# M55M1 register map
File version: 1.0
Registers are 32-bit, read-write, reset 0x0 unless marked. A register's access mark holds for its fields unless they carry their own. Offsets are from the block's base; [hi:lo] are bit positions; {n}, {i} and the like mark numbered series; 'fields as' and 'values as' point back to an identical list.

## GPIO — GPIO Register Map
Base 0x40229000
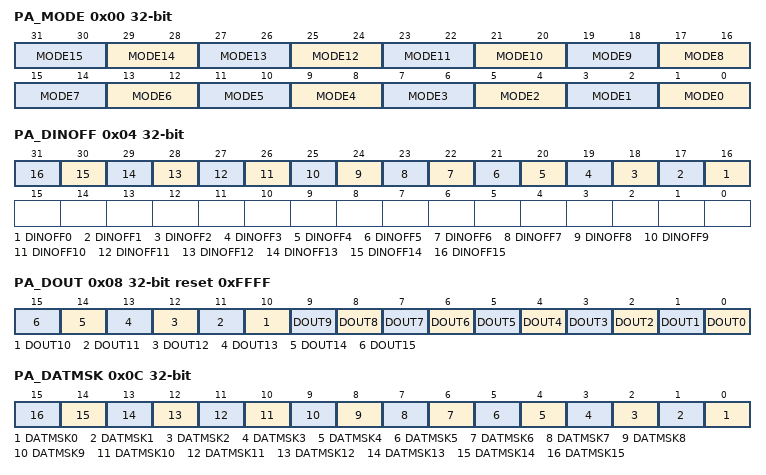
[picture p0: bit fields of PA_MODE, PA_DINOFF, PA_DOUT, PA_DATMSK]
0x00 PA_MODE — PA I/O Mode Control
  [all] fields
    0=Px.n is in Input mode; 1=Px.n is in Push-pull Output mode; 2=Px.n is in Open-drain Output mode; 3=Px.n is in Quasi-bidirectional mode
  [2n+1:2n] MODE{n} (n=0..15) — Port A-J I/O Pin[n] Mode Control. Determine each I/O mode of Px.n pins. Note 2: Each INT pins is Input mode
0x04 PA_DINOFF — PA Digital Input Path Disable Control
  [all] fields
    0=Px.n digital input path Enabled; 1=Px.n digital input path Disabled (digital input tied to low)
  [n+16] DINOFF{n} (n=0..15) — Port A-J Pin[n] Digital Input Path Disable Bit. Each of these bits is used to control if the digital input path of corresponding Px.n pin is disabled. If input is analog signal, users can disable Px.n digital input path to avoid input current leakage.
0x08 PA_DOUT reset 0xFFFF — PA Data Output Value
  [all] fields
    0=Px.n will drive Low if the Px.n pin is configured as Push-pull output, Open-drain output or Quasi-bidirectional mode; 1=Px.n will drive High if the Px.n pin is configured as Push-pull output or Quasi-bidirectional mode
  [n] DOUT{n} (n=0..15) — Port A-J Pin[n] Output Value. Each of these bits controls the status of a Px.n pin when the Px.n is configured as Push-pull output, Open-drain output or Quasi-bidirectional mode.
0x0C PA_DATMSK — PA Data Output Write Mask
  [all] fields
    0=Corresponding DOUT (Px_DOUT[n]) bit can be updated; 1=Corresponding DOUT (Px_DOUT[n]) bit protected
  [n] DATMSK{n} (n=0..15) — Port A-J Pin[n] Data Output Write Mask. These bits are used to protect the corresponding DOUT (Px_DOUT[n]) bit. When the DATMSK (Px_DATMSK[n]) bit is set to 1, the corresponding DOUT (Px_DOUT[n]) bit is protected. If the write signal is masked, writing data to the protect bit is ignored.
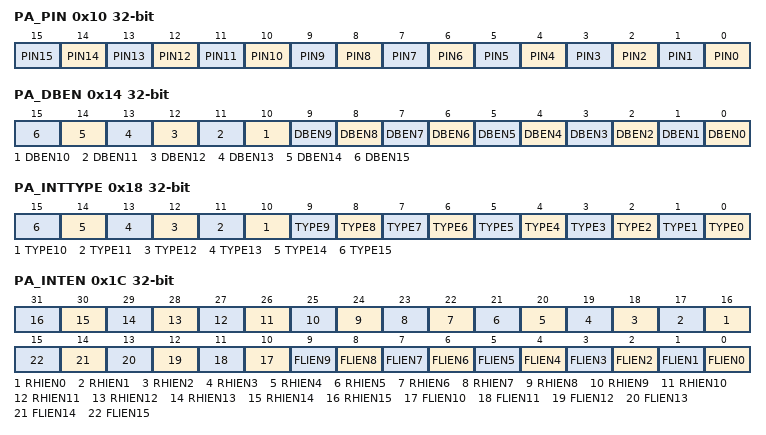
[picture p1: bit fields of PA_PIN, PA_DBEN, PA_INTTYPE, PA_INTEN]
0x10 PA_PIN ro (reset mask 0xFFFF0000) — PA Pin Value
  [n] PIN{n} (n=0..15) — Port A-J Pin[n] Pin Value. Each bit of the register reflects the actual status of the respective Px.n pin. If the bit is 1, it indicates the corresponding pin status is high; else the pin status is low. Note:
0x14 PA_DBEN — PA De-bounce Enable Control Register
  [all] fields
    0=Px.n de-bounce function Disabled; 1=Px.n de-bounce function Enabled
  [n] DBEN{n} (n=0..15) — Port A-J Pin[n] Input Signal De-bounce Enable Bit. The DBEN[n] bit is used to enable the de-bounce function for each corresponding bit. If the input signal pulse width cannot be sampled by continuous two de-bounce sample cycle, the input signal transition is seen as the signal bounce and will not trigger the interrupt. The de-bounce clock source is controlled by DBCLKSRC (GPIO_DBCTL [4]), one de-bounce sample cycle period is controlled by DBCLKSEL (GPIO_DBCTL [3:0]). Note 2: Set Px_DBEN after configuring Px_DBCTL.
0x18 PA_INTTYPE — PA Interrupt Trigger Type Control
  [all] fields
    0=Edge trigger interrupt; 1=Level trigger interrupt
  [n] TYPE{n} (n=0..15) — Port A-J Pin[n] Edge or Level Detection Interrupt Trigger Type Control. TYPE (Px_INTTYPE[n]) bit is used to control the triggered interrupt is by level trigger or by edge trigger. If the interrupt is by edge trigger, the trigger source can be controlled by de-bounce. If the interrupt is by level trigger, the input source is sampled by one HCLK0 clock and generates the interrupt.
0x1C PA_INTEN — PA Interrupt Enable Control Register
  [n+16] RHIEN{n} (n=0..15) — Port A-J Pin[n] Rising Edge or High Level Interrupt Trigger Type Enable Bit. The RHIEN (Px_INTEN[n+16]) bit is used to enable the interrupt for each of the corresponding input Px.n pin. Set bit to 1 also enable the pin wake-up function. When setting the RHIEN (Px_INTEN[n+16]) bit to 1 : If the interrupt is level trigger (TYPE (Px_INTTYPE[n]) bit is set to 1), the input Px.n pin will generate the interrupt while this pin state is at high level. If the interrupt is edge trigger (TYPE (Px_INTTYPE[n]) bit is set to 0), the input Px.n pin will generate the interrupt while this pin state changed from low to high. Note 2: Clear Px_INTTYPE after configuring GPIO and then enable Px_INTEN.
    0=Px.n level high or low to high interrupt Disabled; 1=Px.n level high or low to high interrupt Enabled
  [n] FLIEN{n} (n=0..15) — Port A-J Pin[n] Falling Edge or Low Level Interrupt Trigger Type Enable Bit. The FLIEN (Px_INTEN[n]) bit is used to enable the interrupt for each of the corresponding input Px.n pin. Set bit to 1 also enable the pin wake-up function. When setting the FLIEN (Px_INTEN[n]) bit to 1 : If the interrupt is level trigger (TYPE (Px_INTTYPE[n]) bit is set to 1), the input Px.n pin will generate the interrupt while this pin state is at low level. If the interrupt is edge trigger(TYPE (Px_INTTYPE[n]) bit is set to 0), the input Px.n pin will generate the interrupt while this pin state changed from high to low. Note 2: Write 1 clear Px_INTTYPE after configuring GPIO and then enable Px_INTEN.
    0=Px.n level low or high to low interrupt Disabled; 1=Px.n level low or high to low interrupt Enabled
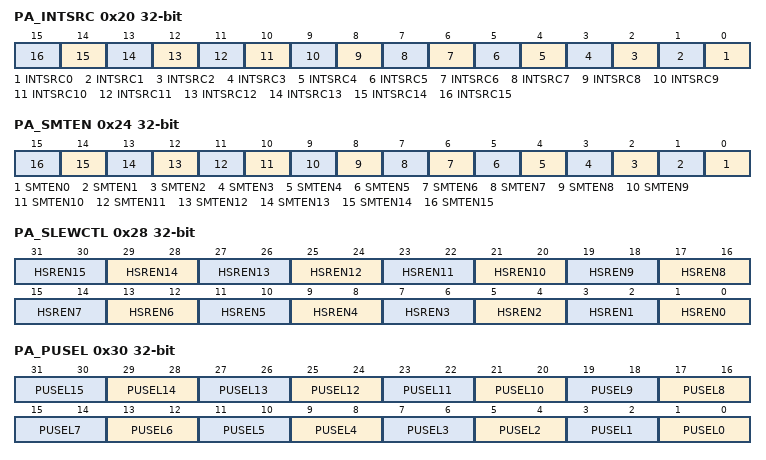
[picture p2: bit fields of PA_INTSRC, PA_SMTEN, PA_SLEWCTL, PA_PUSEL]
0x20 PA_INTSRC (reset mask 0xFFFF0000) — PA Interrupt Source Flag
  [all] fields
    0=No interrupt at Px.n; 1=Px.n generates an interrupt
  [n] INTSRC{n} write-1-clears (n=0..15) — Port A-J Pin[n] Interrupt Source Flag (Write 1 to Clear)
0x24 PA_SMTEN — PA Input Schmitt Trigger Enable Register
  [all] fields
    0=Px.n input schmitt trigger function Disabled; 1=Px.n input schmitt trigger function Enabled
  [n] SMTEN{n} (n=0..15) — Port A-J Pin[n] Input Schmitt Trigger Enable Bit
0x28 PA_SLEWCTL — PA High Slew Rate Control Register
  [all] fields
    0=Px.n output with normal slew rate mode (maximum 20 MHz at 2.7V); 1=Px.n output with high slew rate mode (maximum 40 MHz at 2.7V); 2=Px.n output with fast slew rate mode (maximum 80 MHz at 2.7V); 3=Px.n output with fast slew rate mode (maximum 100 MHz cloud at 35pF / maximum 120 MHz cloud at 25pF at 2.7V)
  [2n+1:2n] HSREN{n} (n=0..15) — Port A-J Pin[n] High Slew Rate Control
0x30 PA_PUSEL — PA Pull-up and Pull-down Selection Register
  [all] fields
    0=Px.n pull-up and pull-down disable; 1=Px.n pull-up enable; 2=Px.n pull-down enable
  [2n+1:2n] PUSEL{n} (n=0..15) — Port A-J Pin[n] Pull-up and Pull-down Enable Register. Determine each I/O Pull-up/pull-down of Px.n pins.
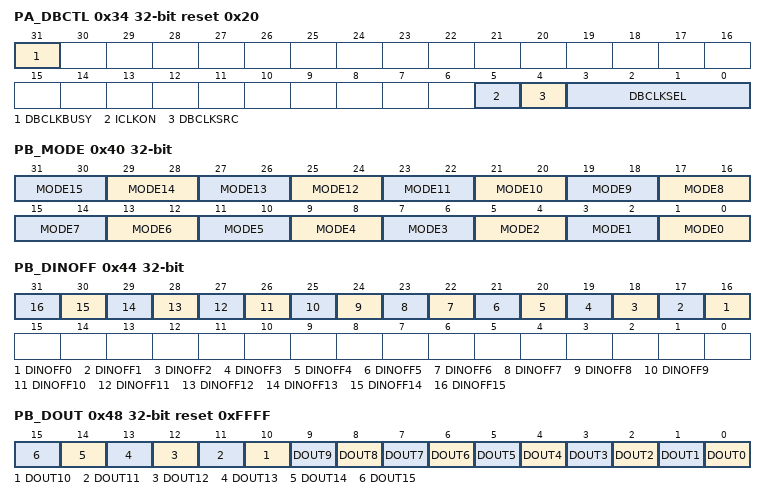
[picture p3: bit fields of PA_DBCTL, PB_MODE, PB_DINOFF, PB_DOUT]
0x34 PA_DBCTL reset 0x20 — PA Interrupt De-bounce Control Register
  [31] DBCLKBUSY ro — De-bounce Clock Switching Busy Flag - Secure Only (Read Only). This bit is set when de-bounce clock source is changed by setting DBCLKSRC(Px_DBCTL[4]). And it is cleared after de-bounce clock source switching is finished. De-bounce function can work normally after de-bounce clock switch done.
    0=De-bounce clock switch done; 1=De-bounce clock is switching
  [5] ICLKON — Interrupt Clock on Mode - Secure Only
    0=Edge detection circuit is active only if I/O pin corresponding RHIEN (Px_INTEN[n+16])/FLIEN (Px_INTEN[n]) bit is set to 1. If corresponding RHIEN or FLIEN is 0, the clock of I/O detect circuit is stopped and interrupt source flag(Px_INTSRC) cannot be clear also; 1=All I/O pins edge detection circuit is always active after reset
  [4] DBCLKSRC — De-bounce Counter Clock Source Selection - Secure Only
    0=De-bounce counter clock source is the HCLK0; 1=De-bounce counter clock source is the 32 kHz internal low speed RC oscillator (LIRC)
  [3:0] DBCLKSEL — De-bounce Sampling Cycle Selection - Secure Only
    0=Sample interrupt input once per 1 clocks; 1=Sample interrupt input once per 2 clocks; 2=Sample interrupt input once per 4 clocks; 3=Sample interrupt input once per 8 clocks; 4=Sample interrupt input once per 16 clocks; 5=Sample interrupt input once per 32 clocks; 6=Sample interrupt input once per 64 clocks; 7=Sample interrupt input once per 128 clocks; 8=Sample interrupt input once per 256 clocks; 9=Sample interrupt input once per 2*256 clocks; 10=Sample interrupt input once per 4*256 clocks; 11=Sample interrupt input once per 8*256 clocks; 12=Sample interrupt input once per 16*256 clocks; 13=Sample interrupt input once per 32*256 clocks; 14=Sample interrupt input once per 64*256 clocks; 15=Sample interrupt input once per 128*256 clocks
0x40 PB_MODE — PB I/O Mode Control
  fields as PA_MODE
0x44 PB_DINOFF — PB Digital Input Path Disable Control
  fields as PA_DINOFF
0x48 PB_DOUT reset 0xFFFF — PB Data Output Value
  fields as PA_DOUT
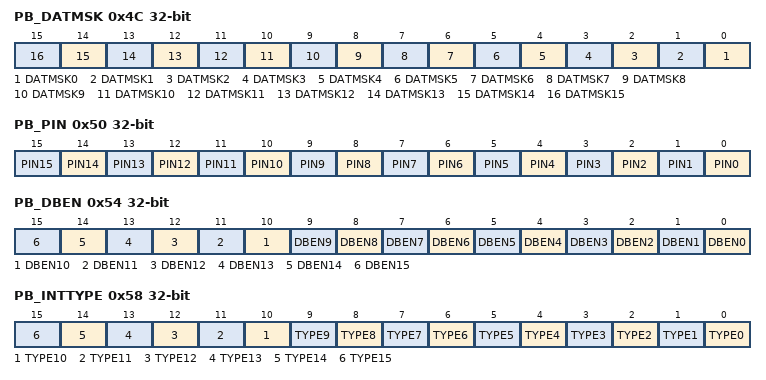
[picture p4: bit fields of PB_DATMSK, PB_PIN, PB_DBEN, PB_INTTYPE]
0x4C PB_DATMSK — PB Data Output Write Mask
  fields as PA_DATMSK
0x50 PB_PIN ro (reset mask 0xFFFF0000) — PB Pin Value
  fields as PA_PIN
0x54 PB_DBEN — PB De-bounce Enable Control Register
  fields as PA_DBEN
0x58 PB_INTTYPE — PB Interrupt Trigger Type Control
  fields as PA_INTTYPE
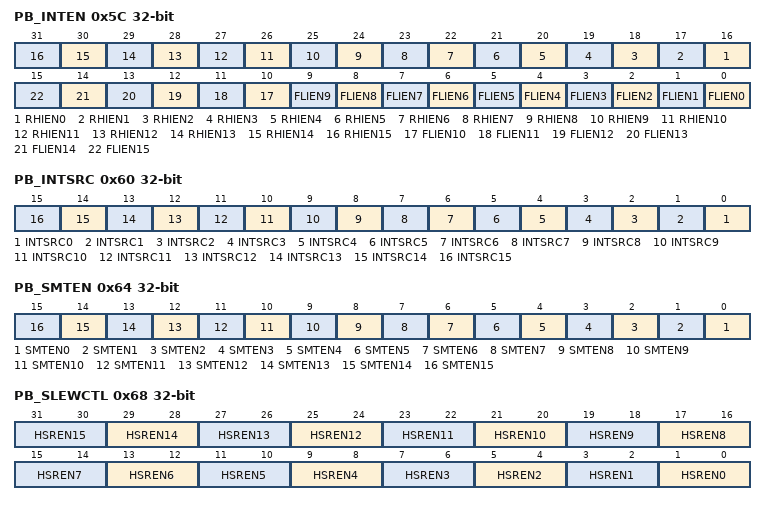
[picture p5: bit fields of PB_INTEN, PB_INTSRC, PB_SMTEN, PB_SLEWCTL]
0x5C PB_INTEN — PB Interrupt Enable Control Register
  fields as PA_INTEN
0x60 PB_INTSRC (reset mask 0xFFFF0000) — PB Interrupt Source Flag
  fields as PA_INTSRC
0x64 PB_SMTEN — PB Input Schmitt Trigger Enable Register
  fields as PA_SMTEN
0x68 PB_SLEWCTL — PB High Slew Rate Control Register
  fields as PA_SLEWCTL
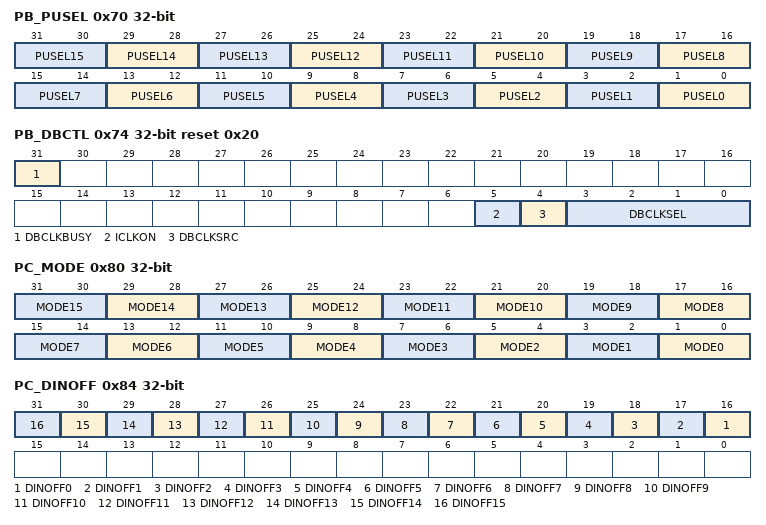
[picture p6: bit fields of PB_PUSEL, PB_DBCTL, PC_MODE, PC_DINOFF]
0x70 PB_PUSEL — PB Pull-up and Pull-down Selection Register
  fields as PA_PUSEL
0x74 PB_DBCTL reset 0x20 — PB Interrupt De-bounce Control Register
  fields as PA_DBCTL
0x80 PC_MODE — PC I/O Mode Control
  fields as PA_MODE
0x84 PC_DINOFF — PC Digital Input Path Disable Control
  fields as PA_DINOFF
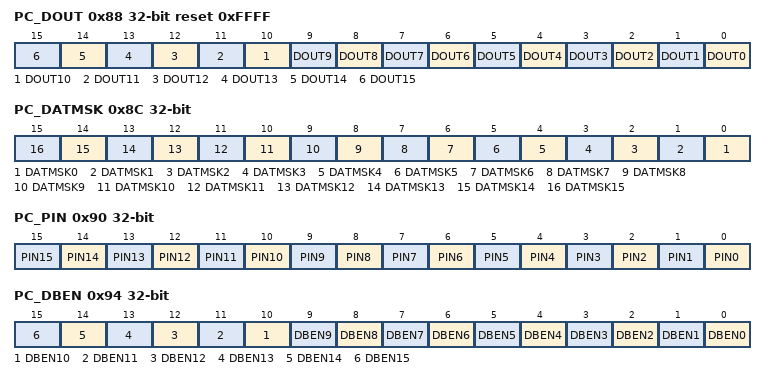
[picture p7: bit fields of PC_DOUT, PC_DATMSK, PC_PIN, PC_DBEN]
0x88 PC_DOUT reset 0xFFFF — PC Data Output Value
  fields as PA_DOUT
0x8C PC_DATMSK — PC Data Output Write Mask
  fields as PA_DATMSK
0x90 PC_PIN ro (reset mask 0xFFFF0000) — PC Pin Value
  fields as PA_PIN
0x94 PC_DBEN — PC De-bounce Enable Control Register
  fields as PA_DBEN
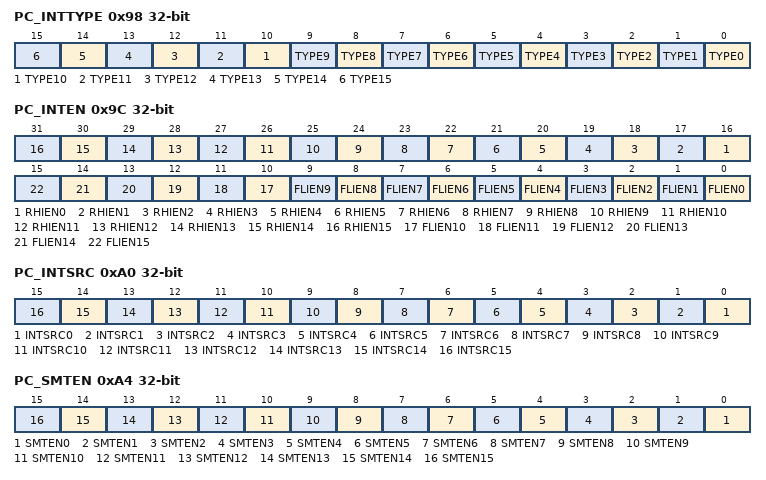
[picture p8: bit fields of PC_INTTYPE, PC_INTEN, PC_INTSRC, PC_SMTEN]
0x98 PC_INTTYPE — PC Interrupt Trigger Type Control
  fields as PA_INTTYPE
0x9C PC_INTEN — PC Interrupt Enable Control Register
  fields as PA_INTEN
0xA0 PC_INTSRC (reset mask 0xFFFF0000) — PC Interrupt Source Flag
  fields as PA_INTSRC
0xA4 PC_SMTEN — PC Input Schmitt Trigger Enable Register
  fields as PA_SMTEN
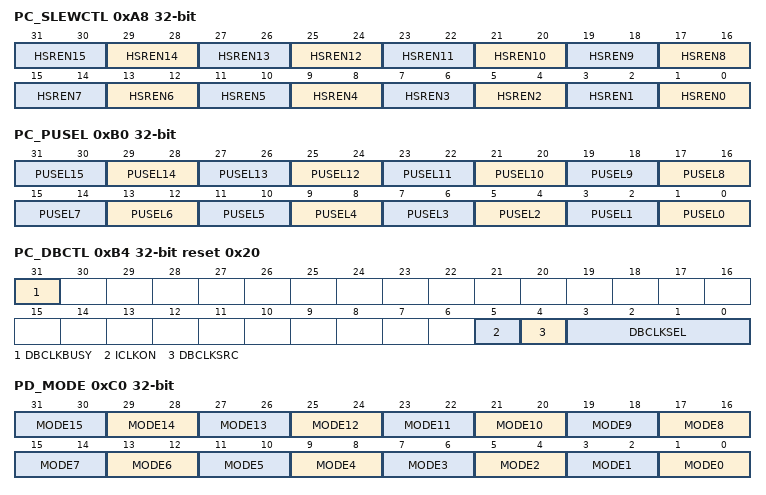
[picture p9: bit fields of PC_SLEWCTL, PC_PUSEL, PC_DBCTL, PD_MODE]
0xA8 PC_SLEWCTL — PC High Slew Rate Control Register
  fields as PA_SLEWCTL
0xB0 PC_PUSEL — PC Pull-up and Pull-down Selection Register
  fields as PA_PUSEL
0xB4 PC_DBCTL reset 0x20 — PC Interrupt De-bounce Control Register
  fields as PA_DBCTL
0xC0 PD_MODE — PD I/O Mode Control
  fields as PA_MODE
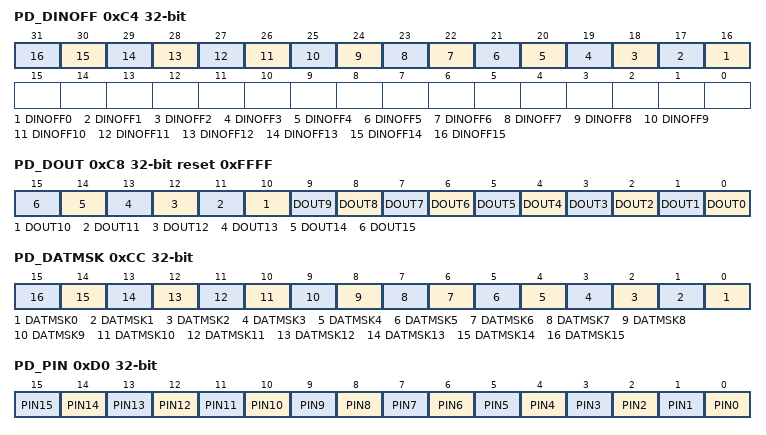
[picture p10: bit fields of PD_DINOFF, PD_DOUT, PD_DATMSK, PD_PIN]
0xC4 PD_DINOFF — PD Digital Input Path Disable Control
  fields as PA_DINOFF
0xC8 PD_DOUT reset 0xFFFF — PD Data Output Value
  fields as PA_DOUT
0xCC PD_DATMSK — PD Data Output Write Mask
  fields as PA_DATMSK
0xD0 PD_PIN ro (reset mask 0xFFFF0000) — PD Pin Value
  fields as PA_PIN
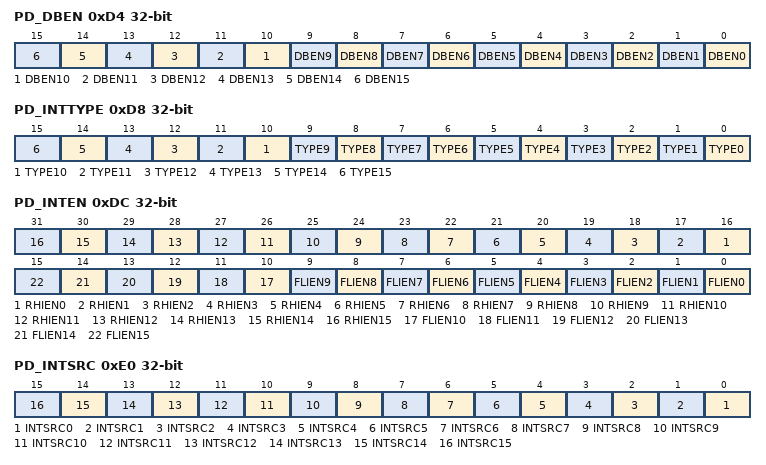
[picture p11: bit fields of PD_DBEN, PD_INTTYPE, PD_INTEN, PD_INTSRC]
0xD4 PD_DBEN — PD De-bounce Enable Control Register
  fields as PA_DBEN
0xD8 PD_INTTYPE — PD Interrupt Trigger Type Control
  fields as PA_INTTYPE
0xDC PD_INTEN — PD Interrupt Enable Control Register
  fields as PA_INTEN
0xE0 PD_INTSRC (reset mask 0xFFFF0000) — PD Interrupt Source Flag
  fields as PA_INTSRC
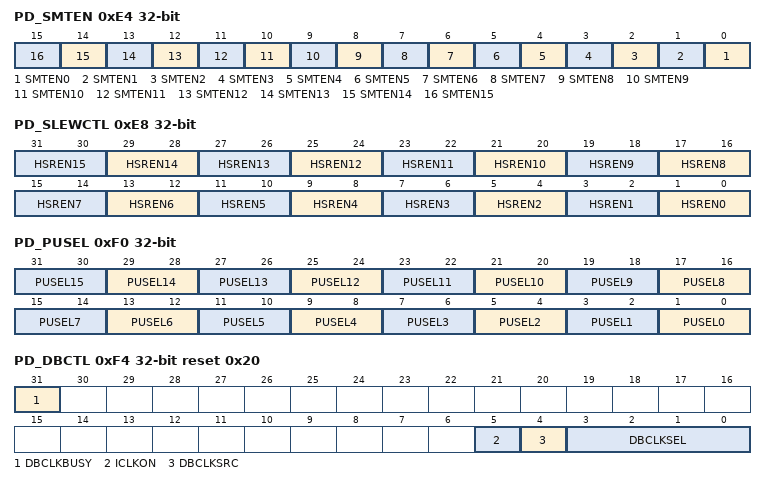
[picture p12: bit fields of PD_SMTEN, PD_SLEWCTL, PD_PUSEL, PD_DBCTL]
0xE4 PD_SMTEN — PD Input Schmitt Trigger Enable Register
  fields as PA_SMTEN
0xE8 PD_SLEWCTL — PD High Slew Rate Control Register
  fields as PA_SLEWCTL
0xF0 PD_PUSEL — PD Pull-up and Pull-down Selection Register
  fields as PA_PUSEL
0xF4 PD_DBCTL reset 0x20 — PD Interrupt De-bounce Control Register
  fields as PA_DBCTL
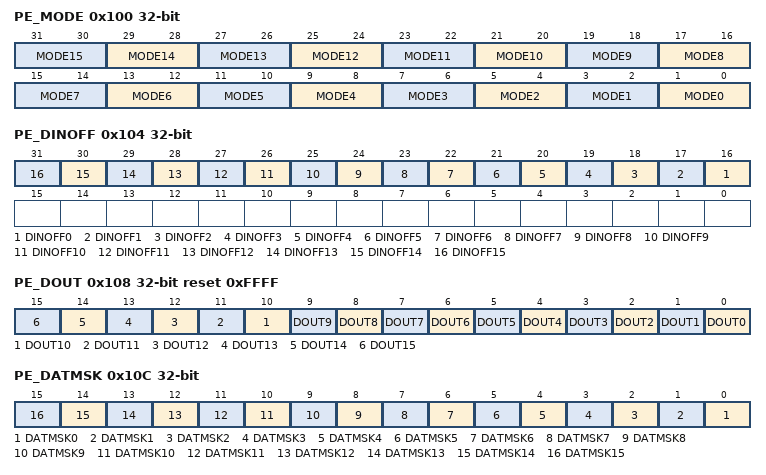
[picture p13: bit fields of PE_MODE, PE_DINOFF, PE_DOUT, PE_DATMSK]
0x100 PE_MODE — PE I/O Mode Control
  fields as PA_MODE
0x104 PE_DINOFF — PE Digital Input Path Disable Control
  fields as PA_DINOFF
0x108 PE_DOUT reset 0xFFFF — PE Data Output Value
  fields as PA_DOUT
0x10C PE_DATMSK — PE Data Output Write Mask
  fields as PA_DATMSK
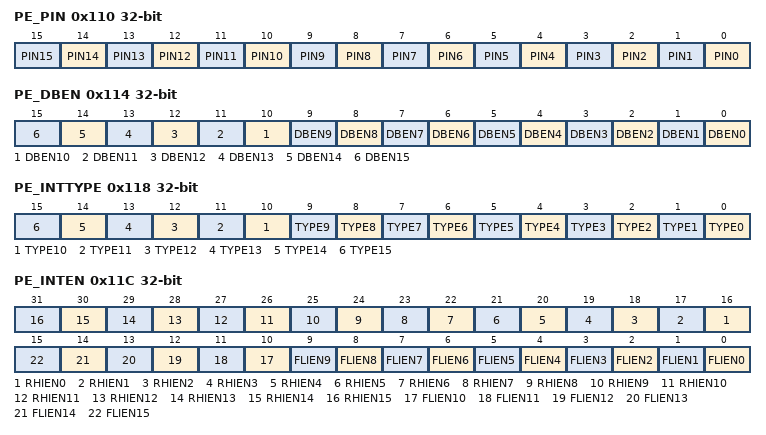
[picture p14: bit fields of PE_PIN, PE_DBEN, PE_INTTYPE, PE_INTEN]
0x110 PE_PIN ro (reset mask 0xFFFF0000) — PE Pin Value
  fields as PA_PIN
0x114 PE_DBEN — PE De-bounce Enable Control Register
  fields as PA_DBEN
0x118 PE_INTTYPE — PE Interrupt Trigger Type Control
  fields as PA_INTTYPE
0x11C PE_INTEN — PE Interrupt Enable Control Register
  fields as PA_INTEN
0x120 PE_INTSRC (reset mask 0xFFFF0000) — PE Interrupt Source Flag
  fields as PA_INTSRC
0x124 PE_SMTEN — PE Input Schmitt Trigger Enable Register
  fields as PA_SMTEN
0x128 PE_SLEWCTL — PE High Slew Rate Control Register
  fields as PA_SLEWCTL
0x130 PE_PUSEL — PE Pull-up and Pull-down Selection Register
  fields as PA_PUSEL
0x134 PE_DBCTL reset 0x20 — PE Interrupt De-bounce Control Register
  fields as PA_DBCTL
0x140 PF_MODE — PF I/O Mode Control
  fields as PA_MODE
0x144 PF_DINOFF — PF Digital Input Path Disable Control
  fields as PA_DINOFF
0x148 PF_DOUT reset 0xFFFF — PF Data Output Value
  fields as PA_DOUT
0x14C PF_DATMSK — PF Data Output Write Mask
  fields as PA_DATMSK
0x150 PF_PIN ro (reset mask 0xFFFF0000) — PF Pin Value
  fields as PA_PIN
0x154 PF_DBEN — PF De-bounce Enable Control Register
  fields as PA_DBEN
0x158 PF_INTTYPE — PF Interrupt Trigger Type Control
  fields as PA_INTTYPE
0x15C PF_INTEN — PF Interrupt Enable Control Register
  fields as PA_INTEN
0x160 PF_INTSRC (reset mask 0xFFFF0000) — PF Interrupt Source Flag
  fields as PA_INTSRC
0x164 PF_SMTEN — PF Input Schmitt Trigger Enable Register
  fields as PA_SMTEN
0x168 PF_SLEWCTL — PF High Slew Rate Control Register
  fields as PA_SLEWCTL
0x170 PF_PUSEL — PF Pull-up and Pull-down Selection Register
  fields as PA_PUSEL
0x174 PF_DBCTL reset 0x20 — PF Interrupt De-bounce Control Register
  fields as PA_DBCTL
0x180 PG_MODE — PG I/O Mode Control
  fields as PA_MODE
0x184 PG_DINOFF — PG Digital Input Path Disable Control
  fields as PA_DINOFF
0x188 PG_DOUT reset 0xFFFF — PG Data Output Value
  fields as PA_DOUT
0x18C PG_DATMSK — PG Data Output Write Mask
  fields as PA_DATMSK
0x190 PG_PIN ro (reset mask 0xFFFF0000) — PG Pin Value
  fields as PA_PIN
0x194 PG_DBEN — PG De-bounce Enable Control Register
  fields as PA_DBEN
0x198 PG_INTTYPE — PG Interrupt Trigger Type Control
  fields as PA_INTTYPE
0x19C PG_INTEN — PG Interrupt Enable Control Register
  fields as PA_INTEN
0x1A0 PG_INTSRC (reset mask 0xFFFF0000) — PG Interrupt Source Flag
  fields as PA_INTSRC
0x1A4 PG_SMTEN — PG Input Schmitt Trigger Enable Register
  fields as PA_SMTEN
0x1A8 PG_SLEWCTL — PG High Slew Rate Control Register
  fields as PA_SLEWCTL
0x1B0 PG_PUSEL — PG Pull-up and Pull-down Selection Register
  fields as PA_PUSEL
0x1B4 PG_DBCTL reset 0x20 — PG Interrupt De-bounce Control Register
  fields as PA_DBCTL
0x1C0 PH_MODE — PH I/O Mode Control
  fields as PA_MODE
0x1C4 PH_DINOFF — PH Digital Input Path Disable Control
  fields as PA_DINOFF
0x1C8 PH_DOUT reset 0xFFFF — PH Data Output Value
  fields as PA_DOUT
0x1CC PH_DATMSK — PH Data Output Write Mask
  fields as PA_DATMSK
0x1D0 PH_PIN ro (reset mask 0xFFFF0000) — PH Pin Value
  fields as PA_PIN
0x1D4 PH_DBEN — PH De-bounce Enable Control Register
  fields as PA_DBEN
0x1D8 PH_INTTYPE — PH Interrupt Trigger Type Control
  fields as PA_INTTYPE
0x1DC PH_INTEN — PH Interrupt Enable Control Register
  fields as PA_INTEN
0x1E0 PH_INTSRC (reset mask 0xFFFF0000) — PH Interrupt Source Flag
  fields as PA_INTSRC
0x1E4 PH_SMTEN — PH Input Schmitt Trigger Enable Register
  fields as PA_SMTEN
0x1E8 PH_SLEWCTL — PH High Slew Rate Control Register
  fields as PA_SLEWCTL
0x1F0 PH_PUSEL — PH Pull-up and Pull-down Selection Register
  fields as PA_PUSEL
0x1F4 PH_DBCTL reset 0x20 — PH Interrupt De-bounce Control Register
  fields as PA_DBCTL
0x200 PI_MODE — PI I/O Mode Control
  fields as PA_MODE
0x204 PI_DINOFF — PI Digital Input Path Disable Control
  fields as PA_DINOFF
0x208 PI_DOUT reset 0xFFFF — PI Data Output Value
  fields as PA_DOUT
0x20C PI_DATMSK — PI Data Output Write Mask
  fields as PA_DATMSK
0x210 PI_PIN ro (reset mask 0xFFFF0000) — PI Pin Value
  fields as PA_PIN
0x214 PI_DBEN — PI De-bounce Enable Control Register
  fields as PA_DBEN
0x218 PI_INTTYPE — PI Interrupt Trigger Type Control
  fields as PA_INTTYPE
0x21C PI_INTEN — PI Interrupt Enable Control Register
  fields as PA_INTEN
0x220 PI_INTSRC (reset mask 0xFFFF0000) — PI Interrupt Source Flag
  fields as PA_INTSRC
0x224 PI_SMTEN — PI Input Schmitt Trigger Enable Register
  fields as PA_SMTEN
0x228 PI_SLEWCTL — PI High Slew Rate Control Register
  fields as PA_SLEWCTL
0x230 PI_PUSEL — PI Pull-up and Pull-down Selection Register
  fields as PA_PUSEL
0x234 PI_DBCTL reset 0x20 — PI Interrupt De-bounce Control Register
  fields as PA_DBCTL
0x240 PJ_MODE — PJ I/O Mode Control
  fields as PA_MODE
0x244 PJ_DINOFF — PJ Digital Input Path Disable Control
  fields as PA_DINOFF
0x248 PJ_DOUT reset 0xFFFF — PJ Data Output Value
  fields as PA_DOUT
0x24C PJ_DATMSK — PJ Data Output Write Mask
  fields as PA_DATMSK
0x250 PJ_PIN ro (reset mask 0xFFFF0000) — PJ Pin Value
  fields as PA_PIN
0x254 PJ_DBEN — PJ De-bounce Enable Control Register
  fields as PA_DBEN
0x258 PJ_INTTYPE — PJ Interrupt Trigger Type Control
  fields as PA_INTTYPE
0x25C PJ_INTEN — PJ Interrupt Enable Control Register
  fields as PA_INTEN
0x260 PJ_INTSRC (reset mask 0xFFFF0000) — PJ Interrupt Source Flag
  fields as PA_INTSRC
0x264 PJ_SMTEN — PJ Input Schmitt Trigger Enable Register
  fields as PA_SMTEN
0x268 PJ_SLEWCTL — PJ High Slew Rate Control Register
  fields as PA_SLEWCTL
0x270 PJ_PUSEL — PJ Pull-up and Pull-down Selection Register
  fields as PA_PUSEL
0x274 PJ_DBCTL reset 0x20 — PJ Interrupt De-bounce Control Register
  fields as PA_DBCTL
{0x440+0x20*i} INT{i}_INNF (i=0..7) — INT{i} Input Noise Filter Register
  [10:8] NFCNT — Noise Filter Count. The register bits control the filter counter to count from 0 to NFCNT.
  [6:4] NFSEL — Noise Filter Clock Selection
    0=Filter clock is HCLK0; 1=Filter clock is HCLK0/2; 2=Filter clock is HCLK0/4; 3=Filter clock is HCLK0/8; 4=Filter clock is HCLK0/16; 5=Filter clock is HCLK0/32; 6=Filter clock is HCLK0/64; 7=Filter clock is HCLK0/128
  [0] NFEN — Noise Filter Enable Bit
    0=Noise Filter function Disabled; 1=Noise Filter function Enabled
{0x444+0x20*i} INT{i}_EDETCTL (i=0..7) — INT{i} Edge Detect Control Register
  [1:0] EDETCTL — INT Edge Detect Control Bits
    0=Not detect; 1=INT low to high detection Enable; 2=INT high to low detection Enable; 3=INT both low to high and high to low detection Enable
{0x448+0x20*i} INT{i}_EDINTEN (i=0..7) — INT{i} Edge Detect Interrupt Enable Control Register
  [0] EDIEN — INT Edge Detect Interrupt Enable Bit. Note: Write 1 clear INTx_EDSTS after configuring EINT and then enable INTx_ EDINTEN.
    0=INT Edge Detect Interrupt Disable; 1=INT Edge Detect Interrupt Enable
{0x44C+0x20*i} INT{i}_EDSTS (i=0..7) — INT{i} Edge Detect Interrupt Flag Register
  [0] EDIF write-1-clears — INT Edge Detect Interrupt Flag (Write 1 to Clear). Note 1: This bit is cleared by writing 1 to it.
    0=No Edge Detection happened; 1=Rising Edge or Falling edge has been detected
{0x800+4i} PA{i}_PDIO (reset mask 0xFFFFFFF0) (i=0..15) — GPIO PA.n Pin Data Input/Output Register
  [0] PDIO — GPIO Px.n Pin Data Input/Output. Writing this bit can control one GPIO pin output value.
    0=Corresponding GPIO pin set to low; 1=Corresponding GPIO pin set to high
{0x840+4i} PB{i}_PDIO (reset mask 0xFFFFFFF0) (i=0..15) — GPIO PB.n Pin Data Input/Output Register
  fields as PA0_PDIO
{0x880+4i} PC{i}_PDIO (reset mask 0xFFFFFFF0) (i=0..13) — GPIO PC.n Pin Data Input/Output Register
  fields as PA0_PDIO
{0x8C0+4i} PD{i}_PDIO (reset mask 0xFFFFFFF0) (i=0..14) — GPIO PD.n Pin Data Input/Output Register
  fields as PA0_PDIO
{0x900+4i} PE{i}_PDIO (reset mask 0xFFFFFFF0) (i=0..15) — GPIO PE.n Pin Data Input/Output Register
  fields as PA0_PDIO
{0x940+4i} PF{i}_PDIO (reset mask 0xFFFFFFF0) (i=0..11) — GPIO PF.n Pin Data Input/Output Register
  fields as PA0_PDIO
{0x980+4i} PG{i}_PDIO (reset mask 0xFFFFFFF0) (i=0..15) — GPIO PG.n Pin Data Input/Output Register
  fields as PA0_PDIO
{0x9C0+4i} PH{i}_PDIO (reset mask 0xFFFFFFF0) (i=0..15) — GPIO PH.n Pin Data Input/Output Register
  fields as PA0_PDIO
{0xA00+4i} PI{i}_PDIO (reset mask 0xFFFFFFF0) (i=6..15) — GPIO PI.n Pin Data Input/Output Register
  fields as PA0_PDIO
{0xA40+4i} PJ{i}_PDIO (reset mask 0xFFFFFFF0) (i=0..13) — GPIO PJ.n Pin Data Input/Output Register
  fields as PA0_PDIO

## GPIO_NS — GPIO Register Map
Base 0x50229000
Registers as GPIO; these are added or differ:
0x14 PA_DBEN — PA De-bounce Enable Control Register
  fields as GPIO.PA_DBEN
0x1C PA_INTEN — PA Interrupt Enable Control Register
  fields as GPIO.PA_INTEN
0x54 PB_DBEN — PB De-bounce Enable Control Register
  fields as GPIO.PA_DBEN
0x5C PB_INTEN — PB Interrupt Enable Control Register
  fields as GPIO.PA_INTEN
0x94 PC_DBEN — PC De-bounce Enable Control Register
  fields as GPIO.PA_DBEN
0x9C PC_INTEN — PC Interrupt Enable Control Register
  fields as GPIO.PA_INTEN
0xD4 PD_DBEN — PD De-bounce Enable Control Register
  fields as GPIO.PA_DBEN
0xDC PD_INTEN — PD Interrupt Enable Control Register
  fields as GPIO.PA_INTEN
0x114 PE_DBEN — PE De-bounce Enable Control Register
  fields as GPIO.PA_DBEN
0x11C PE_INTEN — PE Interrupt Enable Control Register
  fields as GPIO.PA_INTEN
0x154 PF_DBEN — PF De-bounce Enable Control Register
  fields as GPIO.PA_DBEN
0x15C PF_INTEN — PF Interrupt Enable Control Register
  fields as GPIO.PA_INTEN
0x194 PG_DBEN — PG De-bounce Enable Control Register
  fields as GPIO.PA_DBEN
0x19C PG_INTEN — PG Interrupt Enable Control Register
  fields as GPIO.PA_INTEN
0x1D4 PH_DBEN — PH De-bounce Enable Control Register
  fields as GPIO.PA_DBEN
0x1DC PH_INTEN — PH Interrupt Enable Control Register
  fields as GPIO.PA_INTEN
0x214 PI_DBEN — PI De-bounce Enable Control Register
  fields as GPIO.PA_DBEN
0x21C PI_INTEN — PI Interrupt Enable Control Register
  fields as GPIO.PA_INTEN
0x254 PJ_DBEN — PJ De-bounce Enable Control Register
  fields as GPIO.PA_DBEN
0x25C PJ_INTEN — PJ Interrupt Enable Control Register
  fields as GPIO.PA_INTEN
{0x800+4i} PA{i}_PDIO (reset mask 0xFFFFFFF0) (i=0..15) — GPIO PA.n Pin Data Input/Output Register
  [0] PDIO — GPIO Px.n Pin Data Input/Output. Writing this bit can control one GPIO pin output value.
    0=Corresponding GPIO pin set to low; 1=Corresponding GPIO pin set to high
{0x840+4i} PB{i}_PDIO (reset mask 0xFFFFFFF0) (i=0..15) — GPIO PB.n Pin Data Input/Output Register
  fields as PA0_PDIO
{0x880+4i} PC{i}_PDIO (reset mask 0xFFFFFFF0) (i=0..13) — GPIO PC.n Pin Data Input/Output Register
  fields as PA0_PDIO
{0x8C0+4i} PD{i}_PDIO (reset mask 0xFFFFFFF0) (i=0..14) — GPIO PD.n Pin Data Input/Output Register
  fields as PA0_PDIO
{0x900+4i} PE{i}_PDIO (reset mask 0xFFFFFFF0) (i=0..15) — GPIO PE.n Pin Data Input/Output Register
  fields as PA0_PDIO
{0x940+4i} PF{i}_PDIO (reset mask 0xFFFFFFF0) (i=0..11) — GPIO PF.n Pin Data Input/Output Register
  fields as PA0_PDIO
{0x980+4i} PG{i}_PDIO (reset mask 0xFFFFFFF0) (i=0..15) — GPIO PG.n Pin Data Input/Output Register
  fields as PA0_PDIO
{0x9C0+4i} PH{i}_PDIO (reset mask 0xFFFFFFF0) (i=0..15) — GPIO PH.n Pin Data Input/Output Register
  fields as PA0_PDIO
{0xA00+4i} PI{i}_PDIO (reset mask 0xFFFFFFF0) (i=6..15) — GPIO PI.n Pin Data Input/Output Register
  fields as PA0_PDIO
{0xA40+4i} PJ{i}_PDIO (reset mask 0xFFFFFFF0) (i=0..13) — GPIO PJ.n Pin Data Input/Output Register
  fields as PA0_PDIO
